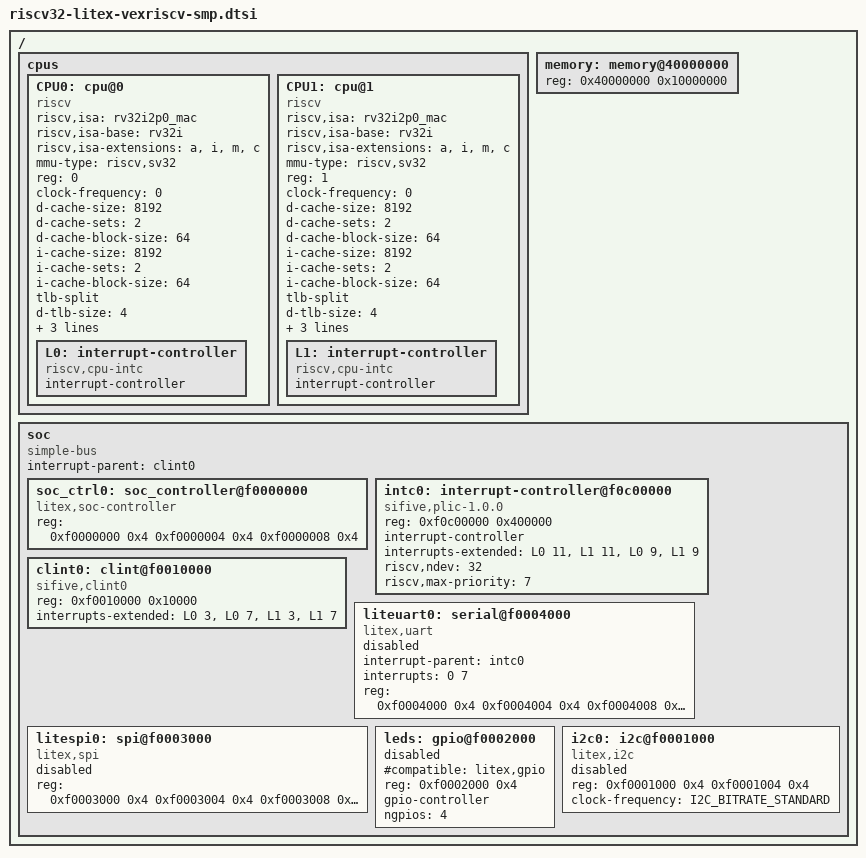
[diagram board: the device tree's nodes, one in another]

/dts-v1/;

#include <zephyr/dt-bindings/i2c/i2c.h>

/ {
	#address-cells = <1>;
	#size-cells    = <1>;

	cpus {
		#address-cells = <1>;
		#size-cells    = <0>;
		// timebase-frequency = <100000000>;

		CPU0: cpu@0 {
			device_type = "cpu";
			compatible = "riscv";
			riscv,isa = "rv32i2p0_mac";
			riscv,isa-base = "rv32i";
			riscv,isa-extensions = "a", "i", "m", "c";
			mmu-type = "riscv,sv32";
			reg = <0>;
			clock-frequency = <0>;
			status = "okay";
			
			d-cache-size = <8192>;
			d-cache-sets = <2>;
			d-cache-block-size = <64>;

			i-cache-size = <8192>;
			i-cache-sets = <2>;
			i-cache-block-size = <64>;

			
			tlb-split;
			d-tlb-size = <4>;
			d-tlb-sets = <4>;

			i-tlb-size = <4>;
			i-tlb-sets = <4>;

			
			L0: interrupt-controller {
				compatible = "riscv,cpu-intc";
				#address-cells = <0>;
				#interrupt-cells = <1>;
				interrupt-controller;
			};
		};

		CPU1: cpu@1 {
			device_type = "cpu";
			compatible = "riscv";
			riscv,isa = "rv32i2p0_mac";
			riscv,isa-base = "rv32i";
			riscv,isa-extensions = "a", "i", "m", "c";
			mmu-type = "riscv,sv32";
			reg = <1>;
			clock-frequency = <0>;
			status = "okay";
			
			d-cache-size = <8192>;
			d-cache-sets = <2>;
			d-cache-block-size = <64>;

			i-cache-size = <8192>;
			i-cache-sets = <2>;
			i-cache-block-size = <64>;

			
			tlb-split;
			d-tlb-size = <4>;
			d-tlb-sets = <4>;

			i-tlb-size = <4>;
			i-tlb-sets = <4>;

			
			L1: interrupt-controller {
				compatible = "riscv,cpu-intc";
				#address-cells = <0>;
				#interrupt-cells = <1>;
				interrupt-controller;
			};
		};
	};

	memory: memory@40000000 {
		device_type = "memory";
		reg = <0x40000000 0x10000000>;
	};

	soc {
		#address-cells = <1>;
		#size-cells    = <1>;
		compatible = "simple-bus";
		interrupt-parent = <&clint0>;
		ranges;

		soc_ctrl0: soc_controller@f0000000 {
			compatible = "litex,soc-controller";
			reg = <0xf0000000 0x4
				0xf0000004 0x4
				0xf0000008 0x4>;
			reg-names = "reset",
				"scratch",
				"bus_errors";
		};

		intc0: interrupt-controller@f0c00000 {
			compatible = "sifive,plic-1.0.0";
			reg = <0xf0c00000 0x400000>;
			#address-cells = <1>;
			#interrupt-cells = <2>;
			interrupt-controller;
			interrupts-extended = <&L0 11 &L1 11 &L0 9 &L1 9>;
			riscv,ndev = <32>;
			riscv,max-priority = <7>;
		};
		
		clint0: clint@f0010000 {
            compatible = "sifive,clint0";
            reg = <0xf0010000 0x10000>;
            interrupts-extended = <&L0 3 &L0 7 &L1 3 &L1 7>;
			interrupt-names = "soft0", "timer0", "soft1", "timer1";
        };

		liteuart0: serial@f0004000 {
			compatible = "litex,uart";
			interrupt-parent = <&intc0>;
			interrupts = <0 7>;
			reg = <0xf0004000 0x4
				0xf0004004 0x4
				0xf0004008 0x4
				0xf000400c 0x4
				0xf0004010 0x4
				0xf0004014 0x4
				0xf0004018 0x4
				0xf000401c 0x4>;
			reg-names =
				"rxtx",
				"txfull",
				"rxempty",
				"ev_status",
				"ev_pending",
				"ev_enable",
				"txempty",
				"rxfull";
			status = "disabled"; 
		};

		litespi0: spi@f0003000 {
			compatible = "litex,spi";
			reg = <0xf0003000 0x4
				0xf0003004 0x4
    	        0xf0003008 0x4
    	        0xf000300c 0x4
    	        0xf0003010 0x4
    	        0xf0003014 0x4>;
			reg-names = "control",
    	      	"status",
    	      	"mosi",
    	      	"miso",
    	      	"cs",
    	      	"loopback";
			status = "disabled";
			#address-cells = <1>;
			#size-cells    = <0>;
		};

		leds: gpio@f0002000 {
		    #compatible = "litex,gpio";
		    reg = <0xf0002000 0x4>;
		    gpio-controller;
		    #gpio-cells = <2>;
		    // litex,direction = "out";
			ngpios = <4>;
		    status = "disabled";
		};
//		mdio0: mdio@f0002800 {
//    	    compatible = "litex,liteeth-mdio";
// 	    	reg = <0xf0002800 0x4>,
//    	        <0xf0002804 0x4>,
//    	        <0xf0002808 0x4>;
//    	    reg-names = "crg_reset",
//    	        "mdio_w",
//    	        "mdio_r";
//    	    #address-cells = <1>;
//    	    #size-cells = <0>;
//    	    status = "disabled";
//			phy0: ethernet-phy@1 {
//                 compatible = "ethernet-phy";
//                 reg = <0>;
//            };
//    	};
//
//    	eth0: ethernet@f0002000 {
//    	    compatible = "litex,liteeth";
//			interrupt-parent = <&intc0>;
//			interrupts = <5 7>;
//			local-mac-address = [02 A1 F3 9C E5 7B];
//			reg = <0xf0002000 0x4
//				0xf0002004 0x4
//				0xf0002008 0x4
//				0xf000200c 0x4
//				0xf0002010 0x4
//				0xf0002014 0x4
//				0xf0002018 0x4
//				0xf000201c 0x4
//				0xf0002020 0x4
//				0xf0002024 0x4
//				0xf0002028 0x4
//				0xf000202c 0x4
//				0xf0002030 0x4
//				0xf0002034 0x4
//				0x80000000 0x2000>;
//    	    reg-names = "rx_slot",
//    	        "rx_length",
//    	        "rx_errors",
//    	        "rx_ev_status",
//    	        "rx_ev_pending",
//    	        "rx_ev_enable",
//    	        "tx_start",
//    	        "tx_ready",
//    	        "tx_level",
//    	        "tx_slot",
//    	        "tx_length",
//    	        "tx_ev_status",
//    	        "tx_ev_pending",
//    	        "tx_ev_enable",
//    	        "buffers";
//			phy-handle = <&phy0>;
//    	    status = "disabled";
//    	};
//
//		timer0: timer@f0001800 {
//            compatible = "litex,timer0";
//            interrupt-parent = <&intc0>;
//            interrupts = <1 0>;
//            reg = <
//				0xf0001800 0x4
//                0xf0001804 0x4
//                0xf0001808 0x4
//                0xf000180c 0x4
//                0xf0001810 0x4
//                0xf0001814 0x4
//                0xf0001818 0x4
//                0xf000181c 0x4
//                0xf0001820 0x4
//                0xf0001824 0x8>;
//            reg-names =
//                "load",
//                "reload",
//                "en",
//                "update_value",
//                "value",
//                "ev_status",
//                "ev_pending",
//                "ev_enable",
//                "uptime_latch",
//                "uptime_cycles";
//            status = "disabled";
//      };

		i2c0: i2c@f0001000 {
			compatible = "litex,i2c";
			reg = <0xf0001000 0x4
				0xf0001004 0x4>;
			reg-names = "write", "read";
			clock-frequency = <I2C_BITRATE_STANDARD>;
			#address-cells = <1>;
			#size-cells = <0>;
			status = "disabled";
		};
	};
};
